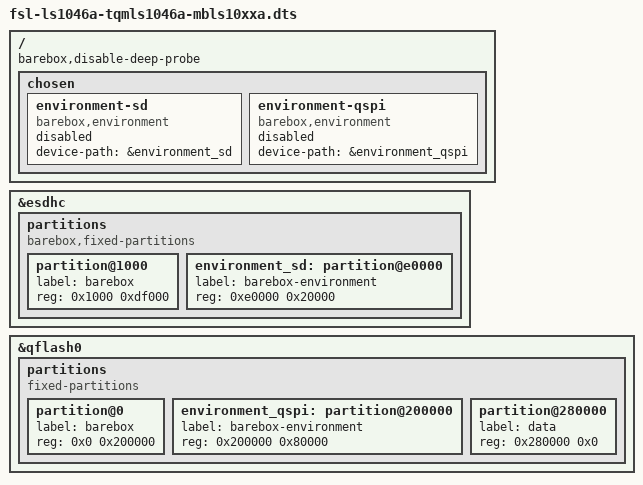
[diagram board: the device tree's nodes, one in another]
// SPDX-License-Identifier: (GPL-2.0+ OR MIT)
/*
 * Device Tree file for TQMLS1046A SoM on MBLS10xxA from TQ
 */

/dts-v1/;

#include <arm64/freescale/fsl-ls1046a-tqmls1046a-mbls10xxa.dts>
#include "fsl-ls1046a.dtsi"

/ {
	barebox,disable-deep-probe;

	chosen {
		environment-sd {
			compatible = "barebox,environment";
			device-path = &environment_sd;
			status = "disabled";
		};

		environment-qspi {
			compatible = "barebox,environment";
			device-path = &environment_qspi;
			status = "disabled";
		};
	};
};

&esdhc {
	partitions {
		#address-cells = <1>;
		#size-cells = <1>;

		compatible = "barebox,fixed-partitions";

		partition@1000 {
			label = "barebox";
			reg = <0x1000 0xdf000>;
		};

		environment_sd: partition@e0000 {
			label = "barebox-environment";
			reg = <0xe0000 0x20000>;
		};
	};
};

&qflash0 {
	partitions {
		#address-cells = <1>;
		#size-cells = <1>;

		compatible = "fixed-partitions";

		partition@0 {
			label = "barebox";
			reg = <0x0 0x200000>;
		};

		environment_qspi: partition@200000 {
			label = "barebox-environment";
			reg = <0x200000 0x80000>;
		};

		partition@280000 {
			label = "data";
			reg = <0x280000 0x0>;
		};
	};
};
